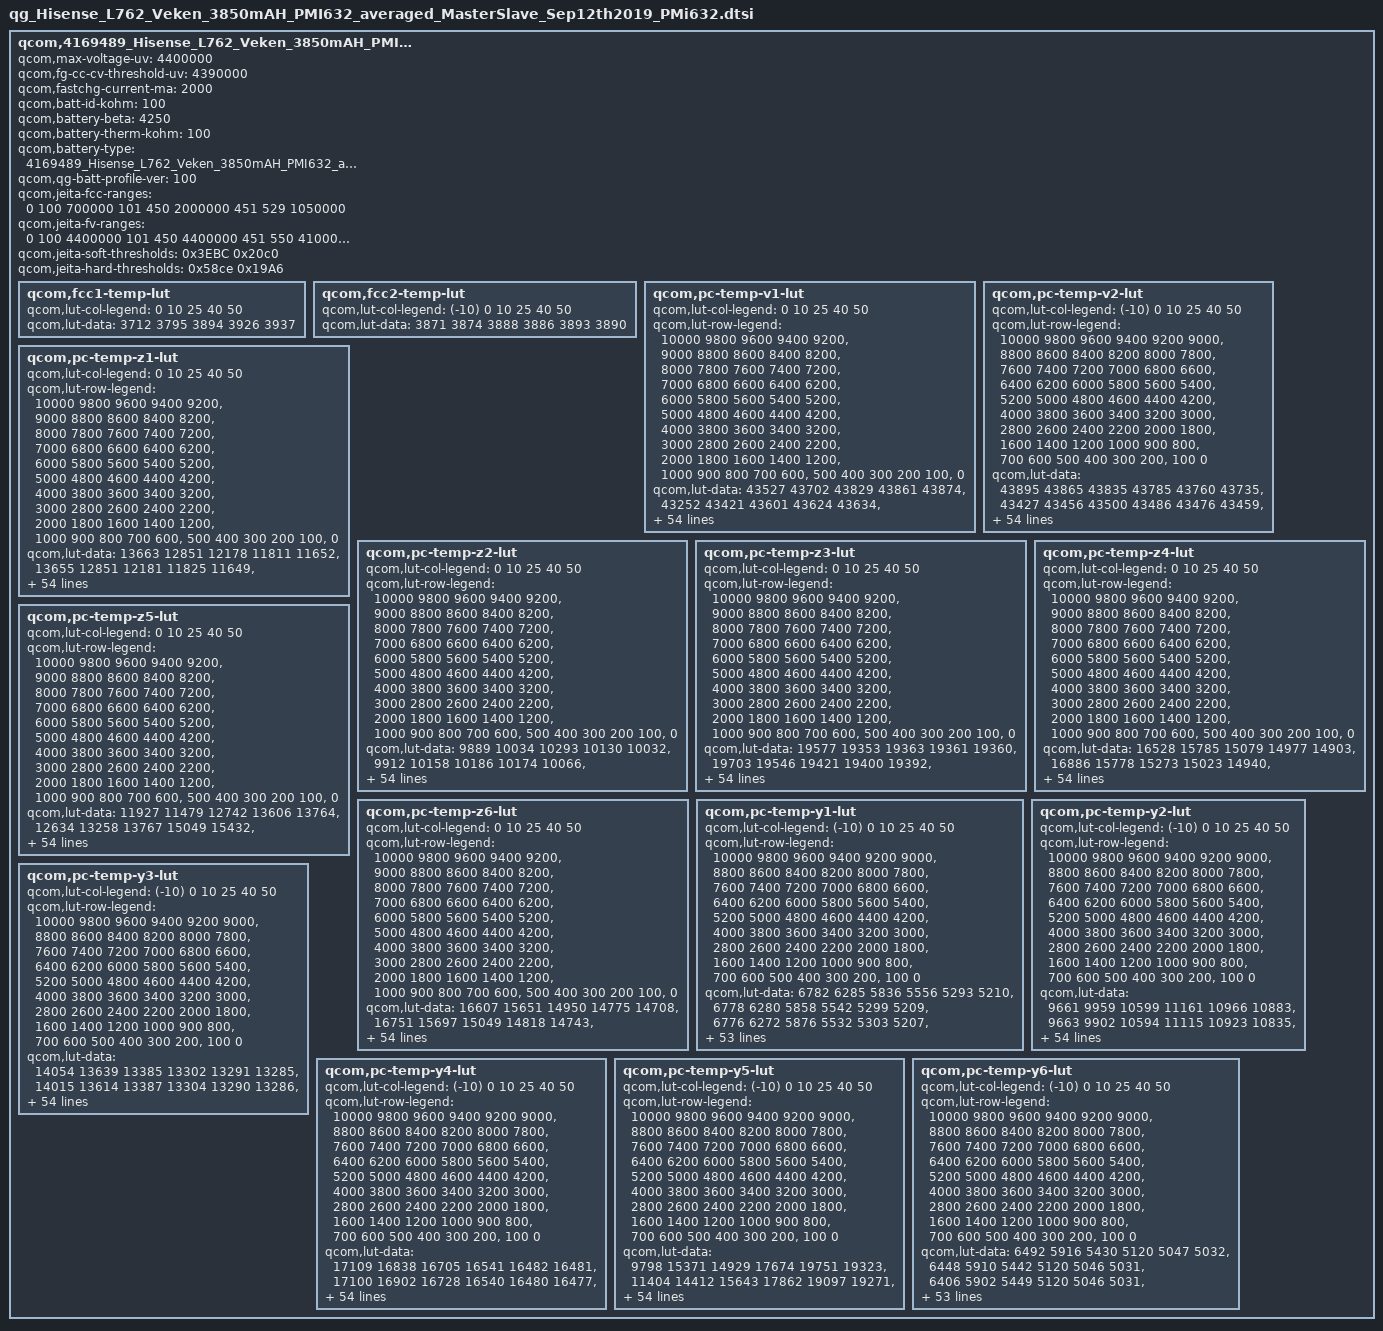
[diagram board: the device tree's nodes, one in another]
qcom,4169489_Hisense_L762_Veken_3850mAH_PMI632 {
    /* 4169489_Hisense_L762_Veken_3850mAH_PMI632_averaged_MasterSlave_Sep12th2019 */
    qcom,max-voltage-uv = <4400000>;
    qcom,fg-cc-cv-threshold-uv = <4390000>;
    qcom,fastchg-current-ma = <2000>;
    qcom,batt-id-kohm = <100>;
    qcom,battery-beta = <4250>;
    qcom,battery-therm-kohm = <100>;
    qcom,battery-type = "4169489_Hisense_L762_Veken_3850mAH_PMI632_averaged_MasterSlave_Sep12th2019";
    qcom,qg-batt-profile-ver = <100>;

	qcom,jeita-fcc-ranges = <0  100   700000
				 101 450  2000000
				 451 529  1050000>;
	qcom,jeita-fv-ranges =  <0  100  4400000
				 101 450  4400000
				 451 550  4100000>;
	/* COOL = 10 DegC, WARM = 45 DegC */
	qcom,jeita-soft-thresholds = <0x3EBC 0x20c0>;
	/* COLD = 0 DegC, HOT = 53 DegC */
	qcom,jeita-hard-thresholds = <0x58ce 0x19A6>;
	qcom,fcc1-temp-lut {
		qcom,lut-col-legend = <0 10 25 40 50>;
		qcom,lut-data = <3712 3795 3894 3926 3937>;
	};

	qcom,fcc2-temp-lut {
		qcom,lut-col-legend = <(-10) 0 10 25 40 50>;
		qcom,lut-data = <3871 3874 3888 3886 3893 3890>;
	};

	qcom,pc-temp-v1-lut {
		qcom,lut-col-legend = <0 10 25 40 50>;
		qcom,lut-row-legend = <10000 9800 9600 9400 9200>,
			<9000 8800 8600 8400 8200>,
			<8000 7800 7600 7400 7200>,
			<7000 6800 6600 6400 6200>,
			<6000 5800 5600 5400 5200>,
			<5000 4800 4600 4400 4200>,
			<4000 3800 3600 3400 3200>,
			<3000 2800 2600 2400 2200>,
			<2000 1800 1600 1400 1200>,
			<1000 900 800 700 600>,
			<500 400 300 200 100>,
			<0>;
		qcom,lut-data = <43527 43702 43829 43861 43874>,
			<43252 43421 43601 43624 43634>,
			<42995 43159 43348 43383 43402>,
			<42752 42914 43095 43144 43165>,
			<42519 42682 42852 42907 42928>,
			<42296 42455 42613 42670 42691>,
			<42082 42236 42379 42435 42455>,
			<41874 42021 42150 42202 42222>,
			<41676 41805 41924 41971 41992>,
			<41484 41594 41699 41744 41765>,
			<41304 41398 41478 41518 41538>,
			<41117 41217 41275 41299 41318>,
			<40908 41027 41092 41085 41101>,
			<40684 40806 40895 40876 40891>,
			<40453 40572 40649 40664 40685>,
			<40188 40341 40394 40454 40485>,
			<39948 40096 40195 40263 40294>,
			<39798 39898 40025 40094 40114>,
			<39691 39778 39868 39932 39941>,
			<39588 39682 39735 39775 39779>,
			<39482 39567 39599 39619 39625>,
			<39378 39431 39403 39430 39442>,
			<39269 39277 39139 39178 39193>,
			<39159 39079 38928 38954 38965>,
			<39047 38857 38783 38809 38818>,
			<38927 38698 38666 38692 38703>,
			<38802 38584 38573 38588 38594>,
			<38690 38496 38497 38493 38490>,
			<38583 38432 38425 38405 38395>,
			<38490 38381 38355 38320 38310>,
			<38425 38340 38291 38243 38234>,
			<38372 38308 38234 38177 38164>,
			<38328 38277 38182 38121 38101>,
			<38291 38247 38135 38067 38041>,
			<38259 38219 38093 38017 37985>,
			<38227 38188 38054 37968 37930>,
			<38196 38158 38017 37921 37874>,
			<38161 38122 37981 37876 37819>,
			<38122 38066 37929 37816 37750>,
			<38073 37980 37846 37728 37659>,
			<38002 37879 37745 37624 37553>,
			<37877 37759 37635 37516 37442>,
			<37733 37620 37507 37393 37317>,
			<37571 37451 37347 37236 37158>,
			<37406 37310 37194 37092 37019>,
			<37287 37204 37090 37000 36940>,
			<37241 37181 37060 36969 36911>,
			<37205 37150 37038 36950 36891>,
			<37175 37120 37024 36932 36872>,
			<37133 37083 36989 36891 36825>,
			<37000 36939 36815 36681 36592>,
			<36604 36535 36405 36262 36171>,
			<36049 35979 35847 35705 35613>,
			<35302 35225 35088 34943 34856>,
			<34127 34055 33913 33769 33673>,
			<30000 30000 30000 30000 30000>;
	};

	qcom,pc-temp-v2-lut {
		qcom,lut-col-legend = <(-10) 0 10 25 40 50>;
		qcom,lut-row-legend = <10000 9800 9600 9400 9200 9000>,
			<8800 8600 8400 8200 8000 7800>,
			<7600 7400 7200 7000 6800 6600>,
			<6400 6200 6000 5800 5600 5400>,
			<5200 5000 4800 4600 4400 4200>,
			<4000 3800 3600 3400 3200 3000>,
			<2800 2600 2400 2200 2000 1800>,
			<1600 1400 1200 1000 900 800>,
			<700 600 500 400 300 200>,
			<100 0>;
		qcom,lut-data = <43895 43865 43835 43785 43760 43735>,
			<43427 43456 43500 43486 43476 43459>,
			<43015 43091 43192 43205 43206 43194>,
			<42672 42778 42917 42943 42949 42941>,
			<42383 42504 42670 42699 42706 42700>,
			<42115 42264 42430 42461 42467 42463>,
			<41834 42062 42185 42224 42232 42229>,
			<41583 41875 41947 41992 42000 41997>,
			<41424 41635 41729 41765 41771 41769>,
			<41314 41329 41526 41544 41545 41543>,
			<41211 41153 41327 41327 41324 41321>,
			<41103 41117 41130 41114 41108 41103>,
			<40967 41089 40933 40904 40896 40889>,
			<40671 40916 40731 40699 40691 40685>,
			<40055 40355 40522 40493 40490 40486>,
			<39596 39896 40299 40287 40296 40294>,
			<39403 39668 40033 40066 40109 40107>,
			<39257 39484 39768 39860 39929 39928>,
			<39080 39297 39561 39708 39762 39761>,
			<38889 39115 39385 39587 39606 39604>,
			<38721 38933 39203 39435 39426 39426>,
			<38579 38736 38998 39193 39195 39202>,
			<38459 38553 38802 38941 38964 38976>,
			<38367 38416 38639 38758 38785 38793>,
			<38292 38302 38495 38606 38629 38630>,
			<38225 38218 38362 38476 38497 38493>,
			<38165 38157 38226 38365 38385 38380>,
			<38109 38107 38114 38266 38286 38281>,
			<38053 38059 38043 38174 38195 38191>,
			<37999 38017 37989 38090 38112 38110>,
			<37944 37975 37943 38014 38040 38037>,
			<37887 37933 37904 37943 37977 37971>,
			<37829 37891 37867 37881 37916 37907>,
			<37768 37848 37830 37827 37849 37840>,
			<37705 37805 37794 37781 37777 37770>,
			<37640 37758 37754 37733 37701 37686>,
			<37572 37706 37711 37684 37618 37581>,
			<37504 37647 37661 37630 37534 37477>,
			<37438 37580 37599 37563 37456 37393>,
			<37373 37505 37524 37485 37378 37315>,
			<37309 37415 37434 37398 37296 37234>,
			<37250 37300 37321 37298 37208 37151>,
			<37190 37185 37198 37182 37094 37040>,
			<37125 37081 37068 37047 36955 36896>,
			<37047 36995 36955 36922 36857 36805>,
			<36934 36921 36877 36865 36808 36758>,
			<36870 36887 36844 36851 36796 36748>,
			<36778 36838 36810 36835 36781 36733>,
			<36642 36755 36748 36804 36755 36703>,
			<36414 36589 36633 36726 36670 36614>,
			<36040 36256 36336 36441 36355 36278>,
			<35523 35741 35823 35975 35857 35780>,
			<34827 35046 35137 35346 35203 35126>,
			<33943 34142 34149 34477 34326 34250>,
			<32741 32959 32725 33232 33085 33031>,
			<30204 29375 28981 28535 28714 29147>;
	};

	qcom,pc-temp-z1-lut {
		qcom,lut-col-legend = <0 10 25 40 50>;
		qcom,lut-row-legend = <10000 9800 9600 9400 9200>,
			<9000 8800 8600 8400 8200>,
			<8000 7800 7600 7400 7200>,
			<7000 6800 6600 6400 6200>,
			<6000 5800 5600 5400 5200>,
			<5000 4800 4600 4400 4200>,
			<4000 3800 3600 3400 3200>,
			<3000 2800 2600 2400 2200>,
			<2000 1800 1600 1400 1200>,
			<1000 900 800 700 600>,
			<500 400 300 200 100>,
			<0>;
		qcom,lut-data = <13663 12851 12178 11811 11652>,
			<13655 12851 12181 11825 11649>,
			<13646 12851 12183 11819 11646>,
			<13636 12849 12185 11811 11638>,
			<13625 12844 12180 11802 11630>,
			<13604 12833 12173 11788 11623>,
			<13589 12807 12164 11777 11617>,
			<13587 12790 12151 11769 11611>,
			<13587 12785 12141 11764 11606>,
			<13579 12782 12136 11760 11603>,
			<13553 12775 12132 11758 11601>,
			<13524 12760 12134 11757 11600>,
			<13501 12743 12144 11759 11599>,
			<13477 12718 12150 11761 11598>,
			<13447 12692 12129 11758 11597>,
			<13399 12689 12099 11748 11596>,
			<13362 12696 12096 11744 11596>,
			<13360 12702 12106 11747 11596>,
			<13367 12702 12112 11751 11597>,
			<13375 12702 12116 11752 11597>,
			<13386 12707 12120 11754 11598>,
			<13398 12729 12125 11756 11598>,
			<13406 12748 12132 11757 11599>,
			<13417 12755 12136 11759 11599>,
			<13425 12759 12136 11761 11600>,
			<13429 12759 12136 11764 11602>,
			<13436 12756 12141 11768 11605>,
			<13442 12755 12149 11773 11609>,
			<13451 12757 12155 11777 11613>,
			<13459 12761 12159 11781 11616>,
			<13458 12766 12163 11785 11619>,
			<13451 12774 12164 11789 11622>,
			<13450 12783 12165 11793 11626>,
			<13471 12792 12167 11797 11630>,
			<13498 12803 12173 11802 11635>,
			<13507 12813 12180 11808 11639>,
			<13508 12824 12185 11813 11643>,
			<13512 12836 12190 11819 11648>,
			<13547 12855 12195 11824 11652>,
			<13597 12882 12202 11827 11656>,
			<13609 12901 12210 11830 11660>,
			<13596 12907 12220 11834 11665>,
			<13597 12913 12229 11840 11670>,
			<13651 12925 12230 11849 11675>,
			<13659 12951 12239 11855 11678>,
			<13631 12925 12239 11857 11680>,
			<13647 12966 12237 11855 11680>,
			<13676 12914 12234 11857 11682>,
			<13674 12937 12259 11859 11685>,
			<13648 12950 12243 11865 11690>,
			<13664 12984 12250 11877 11700>,
			<13731 12964 12276 11888 11711>,
			<13723 12980 12288 11902 11722>,
			<13752 13032 12315 11922 11744>,
			<13752 13032 12315 11922 11744>,
			<13752 13032 12315 11922 11744>;
	};

	qcom,pc-temp-z2-lut {
		qcom,lut-col-legend = <0 10 25 40 50>;
		qcom,lut-row-legend = <10000 9800 9600 9400 9200>,
			<9000 8800 8600 8400 8200>,
			<8000 7800 7600 7400 7200>,
			<7000 6800 6600 6400 6200>,
			<6000 5800 5600 5400 5200>,
			<5000 4800 4600 4400 4200>,
			<4000 3800 3600 3400 3200>,
			<3000 2800 2600 2400 2200>,
			<2000 1800 1600 1400 1200>,
			<1000 900 800 700 600>,
			<500 400 300 200 100>,
			<0>;
		qcom,lut-data = <9889 10034 10293 10130 10032>,
			<9912 10158 10186 10174 10066>,
			<9964 10200 10254 10205 10095>,
			<10004 10176 10306 10236 10118>,
			<10014 10144 10276 10224 10119>,
			<10014 10161 10218 10165 10093>,
			<10016 10267 10222 10117 10066>,
			<10025 10325 10414 10090 10043>,
			<10036 10218 10554 10073 10020>,
			<10039 10069 10415 10073 10002>,
			<10037 10036 10187 10083 9981>,
			<10032 10028 10144 10092 9969>,
			<10013 10025 10154 10093 9957>,
			<9978 10034 10172 10092 9946>,
			<9957 10051 10400 10100 9951>,
			<9946 10061 10714 10115 9960>,
			<9939 10067 10688 10108 9970>,
			<9935 10075 10362 10063 9983>,
			<9933 10088 10182 10027 9999>,
			<9932 10108 10202 10034 10014>,
			<9935 10133 10239 10060 10031>,
			<9943 10173 10283 10106 10066>,
			<9952 10204 10344 10221 10186>,
			<9960 10211 10367 10298 10278>,
			<9969 10209 10324 10240 10228>,
			<9983 10207 10275 10143 10124>,
			<10003 10210 10277 10137 10122>,
			<10022 10215 10300 10213 10271>,
			<10042 10225 10313 10269 10372>,
			<10061 10243 10313 10268 10289>,
			<10075 10255 10312 10249 10139>,
			<10088 10261 10314 10219 10050>,
			<10100 10266 10319 10174 9984>,
			<10112 10274 10321 10152 9959>,
			<10125 10283 10325 10155 9969>,
			<10140 10292 10330 10164 9990>,
			<10161 10299 10342 10170 10018>,
			<10172 10308 10364 10179 10062>,
			<10097 10322 10388 10196 10100>,
			<9966 10347 10418 10254 10134>,
			<9940 10366 10439 10305 10156>,
			<10047 10375 10441 10302 10152>,
			<10137 10385 10441 10290 10142>,
			<10228 10397 10445 10290 10163>,
			<10153 10901 10470 10300 10172>,
			<10471 12468 10514 10256 10132>,
			<10253 12680 10487 10237 10133>,
			<10220 20619 10477 10271 10140>,
			<10461 22290 10473 10283 10167>,
			<10450 17840 10510 10364 10260>,
			<10311 18937 10560 10286 10155>,
			<9942 14584 10511 10148 9992>,
			<9865 15669 10440 10106 9945>,
			<9773 14341 10368 10054 9906>,
			<9773 14341 10368 10054 9906>,
			<9773 14341 10368 10054 9906>;
	};

	qcom,pc-temp-z3-lut {
		qcom,lut-col-legend = <0 10 25 40 50>;
		qcom,lut-row-legend = <10000 9800 9600 9400 9200>,
			<9000 8800 8600 8400 8200>,
			<8000 7800 7600 7400 7200>,
			<7000 6800 6600 6400 6200>,
			<6000 5800 5600 5400 5200>,
			<5000 4800 4600 4400 4200>,
			<4000 3800 3600 3400 3200>,
			<3000 2800 2600 2400 2200>,
			<2000 1800 1600 1400 1200>,
			<1000 900 800 700 600>,
			<500 400 300 200 100>,
			<0>;
		qcom,lut-data = <19577 19353 19363 19361 19360>,
			<19703 19546 19421 19400 19392>,
			<19756 19639 19472 19427 19404>,
			<19786 19663 19501 19443 19419>,
			<19793 19675 19505 19449 19431>,
			<19794 19679 19507 19453 19439>,
			<19793 19681 19510 19454 19443>,
			<19783 19681 19521 19453 19442>,
			<19768 19672 19528 19450 19438>,
			<19765 19660 19517 19446 19434>,
			<19766 19650 19498 19437 19428>,
			<19768 19641 19488 19431 19423>,
			<19771 19632 19478 19428 19418>,
			<19776 19618 19474 19425 19412>,
			<19777 19603 19484 19425 19408>,
			<19785 19597 19498 19424 19405>,
			<19794 19595 19495 19422 19402>,
			<19784 19592 19473 19412 19398>,
			<19749 19571 19455 19402 19393>,
			<19717 19542 19448 19393 19386>,
			<19694 19536 19443 19386 19378>,
			<19676 19542 19445 19386 19377>,
			<19674 19548 19453 19396 19383>,
			<19680 19553 19457 19403 19389>,
			<19687 19559 19447 19394 19382>,
			<19693 19560 19437 19377 19368>,
			<19700 19558 19435 19375 19369>,
			<19703 19556 19435 19391 19407>,
			<19704 19556 19437 19404 19434>,
			<19704 19554 19445 19417 19433>,
			<19700 19553 19453 19431 19428>,
			<19692 19552 19456 19431 19423>,
			<19683 19550 19460 19424 19414>,
			<19675 19548 19460 19417 19405>,
			<19665 19546 19457 19410 19396>,
			<19655 19543 19452 19403 19387>,
			<19645 19538 19447 19396 19380>,
			<19628 19533 19441 19388 19374>,
			<19509 19529 19437 19386 19372>,
			<19319 19526 19435 19386 19371>,
			<19264 19522 19433 19387 19371>,
			<19263 19517 19428 19385 19373>,
			<19262 19511 19422 19383 19377>,
			<19261 19506 19420 19384 19383>,
			<19261 19415 19412 19382 19383>,
			<19260 19355 19399 19368 19365>,
			<19261 19258 19396 19367 19360>,
			<19261 19256 19394 19358 19350>,
			<19260 19256 19367 19352 19345>,
			<19260 19257 19369 19346 19335>,
			<19260 19256 19365 19364 19360>,
			<19262 19258 19365 19384 19379>,
			<19263 19257 19370 19379 19381>,
			<19264 19257 19369 19381 19376>,
			<19264 19257 19369 19381 19376>,
			<19264 19257 19369 19381 19376>;
	};

	qcom,pc-temp-z4-lut {
		qcom,lut-col-legend = <0 10 25 40 50>;
		qcom,lut-row-legend = <10000 9800 9600 9400 9200>,
			<9000 8800 8600 8400 8200>,
			<8000 7800 7600 7400 7200>,
			<7000 6800 6600 6400 6200>,
			<6000 5800 5600 5400 5200>,
			<5000 4800 4600 4400 4200>,
			<4000 3800 3600 3400 3200>,
			<3000 2800 2600 2400 2200>,
			<2000 1800 1600 1400 1200>,
			<1000 900 800 700 600>,
			<500 400 300 200 100>,
			<0>;
		qcom,lut-data = <16528 15785 15079 14977 14903>,
			<16886 15778 15273 15023 14940>,
			<16668 15741 15194 14994 14932>,
			<16346 15574 15100 14934 14895>,
			<16102 15345 15029 14890 14862>,
			<15880 15196 14961 14855 14832>,
			<15698 15074 14898 14824 14805>,
			<15558 14991 14831 14794 14779>,
			<15441 14942 14789 14771 14757>,
			<15340 14904 14776 14757 14747>,
			<15252 14869 14769 14748 14742>,
			<15175 14835 14760 14740 14738>,
			<15106 14810 14750 14733 14733>,
			<15045 14794 14742 14726 14727>,
			<15007 14783 14730 14721 14721>,
			<14987 14781 14715 14717 14715>,
			<14968 14786 14714 14712 14710>,
			<14940 14789 14716 14702 14704>,
			<14904 14775 14714 14696 14699>,
			<14875 14748 14703 14696 14697>,
			<14857 14735 14693 14696 14695>,
			<14842 14726 14715 14706 14699>,
			<14823 14721 14801 14774 14765>,
			<14796 14759 14856 14835 14830>,
			<14776 14841 14878 14854 14844>,
			<14773 14879 14893 14866 14852>,
			<14778 14892 14886 14863 14844>,
			<14786 14895 14863 14829 14788>,
			<14800 14885 14838 14795 14741>,
			<14811 14865 14813 14767 14727>,
			<14811 14846 14790 14742 14719>,
			<14806 14825 14772 14728 14712>,
			<14799 14804 14756 14720 14706>,
			<14790 14786 14748 14716 14704>,
			<14778 14769 14742 14714 14704>,
			<14766 14755 14738 14714 14704>,
			<14752 14740 14735 14714 14704>,
			<14744 14729 14731 14714 14705>,
			<14847 14728 14730 14714 14707>,
			<15032 14730 14734 14723 14720>,
			<15085 14730 14738 14732 14732>,
			<15080 14727 14731 14727 14726>,
			<15071 14723 14719 14717 14713>,
			<15057 14718 14714 14715 14714>,
			<14980 14764 14698 14704 14706>,
			<14958 14797 14680 14685 14684>,
			<14953 14888 14671 14679 14680>,
			<14943 14876 14656 14668 14671>,
			<14933 14866 14667 14649 14649>,
			<14927 14860 14655 14641 14639>,
			<14927 14866 14676 14656 14660>,
			<14961 14894 14699 14660 14668>,
			<14985 14907 14699 14670 14673>,
			<15003 14918 14704 14672 14681>,
			<15003 14918 14704 14672 14681>,
			<15003 14918 14704 14672 14681>;
	};

	qcom,pc-temp-z5-lut {
		qcom,lut-col-legend = <0 10 25 40 50>;
		qcom,lut-row-legend = <10000 9800 9600 9400 9200>,
			<9000 8800 8600 8400 8200>,
			<8000 7800 7600 7400 7200>,
			<7000 6800 6600 6400 6200>,
			<6000 5800 5600 5400 5200>,
			<5000 4800 4600 4400 4200>,
			<4000 3800 3600 3400 3200>,
			<3000 2800 2600 2400 2200>,
			<2000 1800 1600 1400 1200>,
			<1000 900 800 700 600>,
			<500 400 300 200 100>,
			<0>;
		qcom,lut-data = <11927 11479 12742 13606 13764>,
			<12634 13258 13767 15049 15432>,
			<13186 14461 15042 16254 16030>,
			<13661 15157 16068 17160 17220>,
			<14073 15697 16590 17774 18343>,
			<14441 16226 16987 18212 19393>,
			<14755 16712 17785 18696 20359>,
			<14991 17286 19809 19436 21261>,
			<15204 18139 21298 20113 22057>,
			<15517 19185 21591 20413 22478>,
			<16098 20267 21691 20640 22617>,
			<16666 21494 21741 20987 22596>,
			<17205 22413 22109 21624 22675>,
			<17850 23166 22748 22504 22946>,
			<18226 23816 27077 24154 23524>,
			<19692 24026 32655 26524 24616>,
			<21265 24687 32244 27070 25648>,
			<21018 25062 27032 25270 26740>,
			<19419 24027 24267 23738 27489>,
			<18367 22449 27218 23851 27274>,
			<18151 22981 32035 24295 26513>,
			<18016 30466 35926 25056 25986>,
			<18337 38046 40120 26808 26075>,
			<20720 42806 41520 27900 25957>,
			<24186 48032 34997 24543 22781>,
			<29407 48815 26689 18643 17418>,
			<36232 44796 23832 16975 16589>,
			<40062 40286 22114 17472 20066>,
			<43718 37831 21670 18663 23265>,
			<46174 35893 22860 21353 24428>,
			<45455 34800 24632 24536 25281>,
			<43928 34037 26572 25915 26034>,
			<42253 33675 29588 26761 26776>,
			<40430 34247 32413 27548 27120>,
			<38403 35652 35382 28824 27162>,
			<36369 36767 37418 29890 27168>,
			<34128 37541 37671 29646 27127>,
			<31089 38088 37362 28539 26987>,
			<23512 38683 36755 27766 26723>,
			<13775 39976 35478 27427 25514>,
			<11142 40188 33738 27085 24247>,
			<11198 37167 31076 25721 24029>,
			<11237 34605 28543 23921 24287>,
			<11256 33930 27862 24580 26340>,
			<11510 26918 28359 24993 27554>,
			<11505 22167 27339 22044 22238>,
			<11480 11560 26454 21827 20392>,
			<11445 11429 27589 20752 19106>,
			<11405 11414 19566 22319 21477>,
			<11409 11438 21164 22250 22139>,
			<11443 11468 18412 24863 26719>,
			<11520 11426 16264 24137 23631>,
			<11370 11306 16107 20220 21345>,
			<11279 11226 15541 19135 17589>,
			<11279 11226 15541 19135 17589>,
			<11279 11226 15541 19135 17589>;
	};

	qcom,pc-temp-z6-lut {
		qcom,lut-col-legend = <0 10 25 40 50>;
		qcom,lut-row-legend = <10000 9800 9600 9400 9200>,
			<9000 8800 8600 8400 8200>,
			<8000 7800 7600 7400 7200>,
			<7000 6800 6600 6400 6200>,
			<6000 5800 5600 5400 5200>,
			<5000 4800 4600 4400 4200>,
			<4000 3800 3600 3400 3200>,
			<3000 2800 2600 2400 2200>,
			<2000 1800 1600 1400 1200>,
			<1000 900 800 700 600>,
			<500 400 300 200 100>,
			<0>;
		qcom,lut-data = <16607 15651 14950 14775 14708>,
			<16751 15697 15049 14818 14743>,
			<16627 15707 15032 14813 14743>,
			<16442 15622 15007 14796 14736>,
			<16298 15494 14977 14782 14729>,
			<16164 15410 14939 14766 14720>,
			<16048 15341 14909 14750 14709>,
			<15951 15285 14884 14737 14697>,
			<15868 15242 14864 14724 14685>,
			<15800 15207 14847 14714 14677>,
			<15744 15175 14832 14705 14672>,
			<15693 15148 14821 14698 14666>,
			<15636 15122 14812 14693 14661>,
			<15580 15094 14806 14689 14655>,
			<15542 15069 14803 14686 14650>,
			<15519 15061 14800 14682 14645>,
			<15498 15059 14795 14677 14640>,
			<15469 15057 14784 14668 14636>,
			<15433 15042 14776 14660 14631>,
			<15406 15020 14770 14655 14626>,
			<15391 15015 14765 14652 14621>,
			<15380 15018 14776 14656 14622>,
			<15376 15024 14819 14692 14655>,
			<15374 15047 14845 14722 14685>,
			<15374 15086 14852 14724 14686>,
			<15379 15104 14854 14723 14684>,
			<15391 15110 14850 14720 14681>,
			<15400 15113 14841 14714 14678>,
			<15410 15110 14835 14709 14674>,
			<15418 15103 14830 14706 14669>,
			<15418 15097 14826 14702 14663>,
			<15416 15090 14822 14698 14657>,
			<15413 15083 14818 14691 14651>,
			<15409 15077 14815 14686 14646>,
			<15404 15072 14812 14683 14641>,
			<15399 15068 14810 14680 14637>,
			<15393 15064 14808 14676 14634>,
			<15389 15062 14805 14672 14631>,
			<15386 15064 14804 14671 14631>,
			<15383 15070 14808 14676 14636>,
			<15384 15076 14812 14681 14641>,
			<15394 15080 14809 14679 14640>,
			<15406 15084 14805 14675 14638>,
			<15417 15091 14805 14676 14641>,
			<15409 15081 14800 14672 14639>,
			<15404 15074 14790 14657 14621>,
			<15405 15066 14784 14653 14616>,
			<15401 15061 14778 14645 14608>,
			<15400 15060 14770 14634 14595>,
			<15402 15063 14768 14628 14587>,
			<15416 15075 14781 14646 14610>,
			<15443 15096 14796 14662 14627>,
			<15467 15112 14804 14668 14635>,
			<15498 15138 14815 14675 14640>,
			<15498 15138 14815 14675 14640>,
			<15498 15138 14815 14675 14640>;
	};

	qcom,pc-temp-y1-lut {
		qcom,lut-col-legend = <(-10) 0 10 25 40 50>;
		qcom,lut-row-legend = <10000 9800 9600 9400 9200 9000>,
			<8800 8600 8400 8200 8000 7800>,
			<7600 7400 7200 7000 6800 6600>,
			<6400 6200 6000 5800 5600 5400>,
			<5200 5000 4800 4600 4400 4200>,
			<4000 3800 3600 3400 3200 3000>,
			<2800 2600 2400 2200 2000 1800>,
			<1600 1400 1200 1000 900 800>,
			<700 600 500 400 300 200>,
			<100 0>;
		qcom,lut-data = <6782 6285 5836 5556 5293 5210>,
			<6778 6280 5858 5542 5299 5209>,
			<6776 6272 5876 5532 5303 5207>,
			<6774 6266 5888 5524 5305 5205>,
			<6774 6261 5895 5520 5306 5204>,
			<6773 6260 5898 5518 5306 5203>,
			<6775 6262 5892 5522 5304 5202>,
			<6781 6265 5884 5527 5301 5202>,
			<6793 6266 5882 5526 5300 5201>,
			<6819 6265 5883 5519 5298 5200>,
			<6834 6267 5884 5515 5297 5199>,
			<6827 6275 5884 5515 5295 5198>,
			<6818 6284 5885 5515 5293 5197>,
			<6817 6286 5885 5515 5291 5197>,
			<6823 6280 5887 5516 5289 5197>,
			<6826 6278 5889 5517 5289 5197>,
			<6819 6280 5894 5521 5294 5197>,
			<6810 6283 5900 5527 5299 5197>,
			<6811 6287 5905 5527 5299 5197>,
			<6819 6292 5909 5526 5296 5197>,
			<6822 6293 5910 5525 5295 5197>,
			<6815 6290 5907 5526 5295 5197>,
			<6808 6287 5904 5527 5296 5198>,
			<6810 6288 5904 5529 5297 5199>,
			<6823 6294 5906 5534 5301 5201>,
			<6835 6296 5907 5536 5304 5203>,
			<6843 6286 5905 5536 5306 5205>,
			<6849 6276 5904 5535 5307 5207>,
			<6846 6275 5903 5537 5310 5208>,
			<6835 6279 5901 5542 5314 5210>,
			<6831 6281 5899 5545 5317 5212>,
			<6838 6287 5898 5547 5320 5215>,
			<6846 6295 5899 5548 5324 5218>,
			<6838 6289 5903 5550 5327 5220>,
			<6813 6274 5912 5553 5330 5222>,
			<6804 6268 5913 5554 5332 5224>,
			<6823 6276 5908 5555 5336 5226>,
			<6844 6284 5902 5555 5338 5228>,
			<6834 6285 5900 5560 5338 5230>,
			<6799 6280 5900 5570 5338 5232>,
			<6783 6278 5902 5576 5339 5234>,
			<6782 6286 5910 5581 5342 5235>,
			<6782 6286 5909 5583 5346 5238>,
			<6787 6269 5900 5584 5351 5242>,
			<6842 6286 5902 5587 5359 5245>,
			<6867 6332 5921 5595 5364 5250>,
			<6893 6323 5932 5596 5361 5249>,
			<6918 6334 5922 5608 5361 5248>,
			<6913 6324 5930 5596 5360 5250>,
			<7014 6339 5952 5598 5365 5251>,
			<7062 6343 5957 5595 5365 5253>,
			<6930 6366 5950 5608 5375 5259>,
			<7017 6376 5981 5612 5380 5267>,
			<7133 6416 6003 5630 5396 5278>,
			<7133 6416 6003 5630 5396 5278>,
			<7133 6416 6003 5630 5396 5278>;
	};

	qcom,pc-temp-y2-lut {
		qcom,lut-col-legend = <(-10) 0 10 25 40 50>;
		qcom,lut-row-legend = <10000 9800 9600 9400 9200 9000>,
			<8800 8600 8400 8200 8000 7800>,
			<7600 7400 7200 7000 6800 6600>,
			<6400 6200 6000 5800 5600 5400>,
			<5200 5000 4800 4600 4400 4200>,
			<4000 3800 3600 3400 3200 3000>,
			<2800 2600 2400 2200 2000 1800>,
			<1600 1400 1200 1000 900 800>,
			<700 600 500 400 300 200>,
			<100 0>;
		qcom,lut-data = <9661 9959 10599 11161 10966 10883>,
			<9663 9902 10594 11115 10923 10835>,
			<9665 9899 10594 11071 10875 10789>,
			<9668 9930 10598 11030 10828 10746>,
			<9670 9980 10604 10991 10788 10709>,
			<9671 10029 10611 10956 10760 10679>,
			<9672 10110 10626 10922 10740 10654>,
			<9673 10200 10641 10891 10725 10635>,
			<9672 10202 10618 10871 10714 10626>,
			<9670 10094 10517 10856 10699 10620>,
			<9668 10031 10467 10838 10695 10617>,
			<9669 10106 10718 10804 10717 10614>,
			<9670 10231 11034 10774 10742 10609>,
			<9670 10294 11025 10794 10740 10600>,
			<9668 10248 10863 10889 10722 10585>,
			<9667 10204 10788 10968 10715 10579>,
			<9667 9993 10877 11008 10767 10606>,
			<9667 9732 10993 11046 10852 10656>,
			<9667 9697 11037 11122 10932 10726>,
			<9666 9691 11063 11239 11020 10836>,
			<9666 9686 11073 11285 11048 10896>,
			<9666 9682 11071 11238 11013 10923>,
			<9666 9679 11063 11178 10978 10937>,
			<9665 9679 11051 11156 10976 10918>,
			<9665 9679 11026 11141 10975 10875>,
			<9665 9679 10966 11138 10980 10860>,
			<9664 9677 10626 11191 11013 10879>,
			<9664 9674 10282 11247 11049 10908>,
			<9664 9673 10253 11255 11058 10937>,
			<9664 9671 10351 11256 11056 10969>,
			<9664 9669 10394 11256 11061 10987>,
			<9664 9668 10416 11258 11097 10995>,
			<9663 9667 10429 11257 11129 11004>,
			<9663 9666 10277 11251 11137 11027>,
			<9663 9664 9946 11241 11143 11058>,
			<9663 9664 9793 11227 11133 11057>,
			<9662 9663 9741 11201 11097 10983>,
			<9662 9662 9711 11168 11065 10912>,
			<9662 9662 9694 11120 11052 10900>,
			<9661 9661 9683 11054 11041 10907>,
			<9661 9661 9676 10986 11027 10913>,
			<9661 9660 9672 10917 11003 10919>,
			<9661 9660 9669 10849 10970 10891>,
			<9661 9660 9666 10782 10922 10818>,
			<9660 9659 9664 10701 10844 10696>,
			<9660 9659 9664 10694 10789 10640>,
			<9660 9659 9663 10687 10805 10647>,
			<9659 9659 9662 10690 10797 10713>,
			<9659 9658 9661 10697 10849 10686>,
			<9658 9658 9661 10689 10865 10702>,
			<9658 9658 9660 10653 10852 10654>,
			<9658 9657 9659 10602 10791 10581>,
			<9655 9657 9658 10561 10687 10513>,
			<9656 9655 9657 10512 10613 10460>,
			<9656 9655 9657 10512 10613 10460>,
			<9656 9655 9657 10512 10613 10460>;
	};

	qcom,pc-temp-y3-lut {
		qcom,lut-col-legend = <(-10) 0 10 25 40 50>;
		qcom,lut-row-legend = <10000 9800 9600 9400 9200 9000>,
			<8800 8600 8400 8200 8000 7800>,
			<7600 7400 7200 7000 6800 6600>,
			<6400 6200 6000 5800 5600 5400>,
			<5200 5000 4800 4600 4400 4200>,
			<4000 3800 3600 3400 3200 3000>,
			<2800 2600 2400 2200 2000 1800>,
			<1600 1400 1200 1000 900 800>,
			<700 600 500 400 300 200>,
			<100 0>;
		qcom,lut-data = <14054 13639 13385 13302 13291 13285>,
			<14015 13614 13387 13304 13290 13286>,
			<13973 13594 13391 13305 13290 13286>,
			<13930 13581 13396 13306 13290 13287>,
			<13886 13573 13400 13308 13290 13287>,
			<13842 13573 13401 13309 13290 13288>,
			<13800 13586 13401 13310 13291 13288>,
			<13756 13605 13400 13312 13291 13289>,
			<13696 13585 13408 13313 13292 13289>,
			<13612 13476 13438 13316 13292 13290>,
			<13571 13409 13454 13318 13293 13291>,
			<13586 13407 13410 13319 13296 13292>,
			<13608 13410 13353 13320 13300 13293>,
			<13605 13417 13350 13321 13302 13295>,
			<13581 13430 13363 13324 13303 13297>,
			<13566 13436 13369 13324 13304 13299>,
			<13565 13436 13368 13317 13305 13300>,
			<13567 13435 13365 13309 13306 13300>,
			<13570 13434 13361 13309 13305 13300>,
			<13576 13432 13354 13313 13302 13300>,
			<13579 13429 13348 13314 13298 13299>,
			<13576 13419 13341 13309 13294 13295>,
			<13574 13405 13335 13303 13291 13289>,
			<13578 13391 13331 13301 13289 13287>,
			<13594 13376 13327 13299 13289 13285>,
			<13612 13371 13320 13299 13288 13284>,
			<13630 13383 13289 13298 13287 13283>,
			<13649 13404 13262 13298 13287 13283>,
			<13670 13423 13266 13298 13286 13283>,
			<13695 13445 13282 13297 13284 13284>,
			<13721 13469 13292 13296 13284 13284>,
			<13750 13495 13305 13296 13286 13283>,
			<13782 13525 13320 13296 13287 13282>,
			<13815 13559 13330 13296 13287 13283>,
			<13850 13598 13338 13297 13286 13284>,
			<13888 13639 13348 13297 13286 13285>,
			<13927 13680 13359 13298 13286 13284>,
			<13968 13722 13373 13300 13286 13284>,
			<14008 13765 13391 13301 13287 13284>,
			<14049 13810 13412 13302 13288 13286>,
			<14090 13848 13437 13304 13289 13288>,
			<14129 13880 13467 13306 13290 13289>,
			<14173 13913 13502 13308 13289 13288>,
			<14222 13951 13544 13311 13285 13285>,
			<14278 13998 13592 13311 13287 13287>,
			<14247 13986 13603 13311 13294 13293>,
			<14308 14032 13639 13318 13299 13296>,
			<14370 14076 13683 13325 13301 13299>,
			<14431 14119 13716 13331 13304 13298>,
			<14496 14156 13754 13336 13303 13297>,
			<14564 14192 13772 13332 13299 13293>,
			<14679 14262 13855 13338 13300 13294>,
			<15006 14366 13998 13344 13306 13300>,
			<16166 14574 14158 13357 13317 13313>,
			<16166 14574 14158 13357 13317 13313>,
			<16166 14574 14158 13357 13317 13313>;
	};

	qcom,pc-temp-y4-lut {
		qcom,lut-col-legend = <(-10) 0 10 25 40 50>;
		qcom,lut-row-legend = <10000 9800 9600 9400 9200 9000>,
			<8800 8600 8400 8200 8000 7800>,
			<7600 7400 7200 7000 6800 6600>,
			<6400 6200 6000 5800 5600 5400>,
			<5200 5000 4800 4600 4400 4200>,
			<4000 3800 3600 3400 3200 3000>,
			<2800 2600 2400 2200 2000 1800>,
			<1600 1400 1200 1000 900 800>,
			<700 600 500 400 300 200>,
			<100 0>;
		qcom,lut-data = <17109 16838 16705 16541 16482 16481>,
			<17100 16902 16728 16540 16480 16477>,
			<17102 16958 16762 16539 16479 16474>,
			<17113 17003 16797 16538 16478 16472>,
			<17126 17033 16823 16536 16477 16470>,
			<17137 17043 16834 16536 16476 16469>,
			<17147 17027 16831 16535 16477 16470>,
			<17163 17005 16827 16535 16478 16471>,
			<17237 17037 16815 16535 16481 16472>,
			<17484 17217 16783 16539 16485 16473>,
			<17636 17395 16769 16544 16487 16475>,
			<17636 17539 16910 16547 16487 16477>,
			<17604 17647 17088 16552 16487 16480>,
			<17466 17559 17100 16563 16490 16483>,
			<17061 17143 17053 16587 16501 16486>,
			<16837 16896 17006 16609 16512 16491>,
			<16829 16870 16910 16627 16521 16497>,
			<16824 16854 16811 16646 16533 16507>,
			<16801 16831 16788 16666 16558 16526>,
			<16748 16793 16781 16694 16596 16557>,
			<16718 16749 16766 16702 16609 16568>,
			<16712 16688 16713 16638 16572 16546>,
			<16708 16637 16652 16558 16525 16516>,
			<16708 16634 16614 16527 16499 16495>,
			<16708 16639 16585 16507 16478 16475>,
			<16708 16642 16577 16500 16473 16468>,
			<16707 16641 16600 16498 16474 16470>,
			<16706 16640 16622 16497 16477 16473>,
			<16708 16641 16613 16498 16483 16478>,
			<16713 16644 16583 16501 16494 16487>,
			<16718 16649 16571 16502 16504 16497>,
			<16723 16657 16559 16502 16516 16513>,
			<16727 16668 16552 16501 16522 16523>,
			<16732 16680 16566 16502 16521 16524>,
			<16738 16694 16595 16505 16516 16524>,
			<16743 16708 16621 16507 16509 16521>,
			<16748 16722 16648 16509 16491 16496>,
			<16756 16734 16670 16510 16480 16477>,
			<16767 16738 16686 16511 16480 16478>,
			<16787 16740 16699 16513 16481 16481>,
			<16811 16737 16701 16517 16484 16487>,
			<16846 16714 16697 16532 16495 16501>,
			<16884 16696 16689 16540 16493 16497>,
			<16923 16686 16675 16543 16477 16465>,
			<16930 16696 16667 16546 16475 16461>,
			<16835 16698 16664 16539 16480 16480>,
			<16850 16721 16686 16554 16503 16513>,
			<16865 16757 16720 16574 16537 16546>,
			<16879 16792 16772 16606 16571 16582>,
			<16880 16809 16813 16636 16586 16591>,
			<16874 16800 16801 16596 16511 16498>,
			<16902 16800 16777 16600 16497 16490>,
			<17076 16827 16790 16619 16509 16492>,
			<18644 17065 16835 16666 16559 16527>,
			<18644 17065 16835 16666 16559 16527>,
			<18644 17065 16835 16666 16559 16527>;
	};

	qcom,pc-temp-y5-lut {
		qcom,lut-col-legend = <(-10) 0 10 25 40 50>;
		qcom,lut-row-legend = <10000 9800 9600 9400 9200 9000>,
			<8800 8600 8400 8200 8000 7800>,
			<7600 7400 7200 7000 6800 6600>,
			<6400 6200 6000 5800 5600 5400>,
			<5200 5000 4800 4600 4400 4200>,
			<4000 3800 3600 3400 3200 3000>,
			<2800 2600 2400 2200 2000 1800>,
			<1600 1400 1200 1000 900 800>,
			<700 600 500 400 300 200>,
			<100 0>;
		qcom,lut-data = <9798 15371 14929 17674 19751 19323>,
			<11404 14412 15643 17862 19097 19271>,
			<12729 14105 16354 17977 18456 19120>,
			<13736 14316 16970 18030 17854 18889>,
			<14386 14913 17400 18029 17314 18600>,
			<14640 15770 17552 17983 16860 18273>,
			<14327 18138 17388 17764 16484 17817>,
			<13821 20867 17162 17486 16154 17314>,
			<13706 20124 17950 17360 15790 16955>,
			<13687 14814 21322 17089 15293 16673>,
			<14042 11777 23066 16757 15081 16416>,
			<17812 13989 18671 15884 15697 16075>,
			<22598 17473 13109 14941 16464 15799>,
			<22030 19190 13717 14818 16350 15864>,
			<16700 20110 18307 14850 15606 16190>,
			<13758 20323 20757 14848 15109 16329>,
			<14413 18728 20977 14496 14905 15753>,
			<15279 16965 21141 14102 14791 15062>,
			<15344 17483 21614 14871 14791 14932>,
			<15075 18778 22458 17741 14830 14885>,
			<14677 19337 22974 20111 14994 14973>,
			<13719 18436 23171 21803 17064 17191>,
			<12762 16856 23348 22917 19493 19514>,
			<12646 15151 23762 23036 20434 19557>,
			<12645 13072 24449 22938 21082 19142>,
			<12655 12235 24318 22859 21187 18582>,
			<12822 12338 18167 22756 20150 17530>,
			<13067 12519 12192 22608 18793 16605>,
			<13219 12663 12289 22417 17733 16325>,
			<13341 12870 13401 22189 16766 16162>,
			<13438 13041 14103 22106 16641 16087>,
			<13565 13226 14893 22159 17966 16040>,
			<13673 13401 15504 22214 19272 16019>,
			<13707 13571 15293 22249 19660 16964>,
			<13722 13879 14623 22328 19977 19078>,
			<13690 14119 14327 22314 20293 20053>,
			<13602 14273 14231 22005 20784 20440>,
			<13507 14410 14183 21533 21089 20641>,
			<13411 14641 14229 20705 20886 20781>,
			<13247 15028 14331 19335 20419 20990>,
			<13106 15186 14353 18156 20012 21074>,
			<13021 14896 14299 17037 19637 21178>,
			<13084 14574 14237 16327 18552 20708>,
			<13335 14269 14134 15885 16348 18999>,
			<13764 13800 14050 15213 16024 17594>,
			<14553 13739 14046 15656 17142 17524>,
			<15013 13960 13882 15805 16982 16243>,
			<15426 14031 14220 16254 16334 15898>,
			<15949 14329 14253 16214 16383 15244>,
			<16161 15061 14972 16583 16261 15101>,
			<15619 15038 14660 17387 17728 16440>,
			<15428 14861 14196 18747 19201 16483>,
			<15188 15683 14379 18758 19800 17517>,
			<13141 17069 15162 19485 23597 24965>,
			<13141 17069 15162 19485 23597 24965>,
			<13141 17069 15162 19485 23597 24965>;
	};

	qcom,pc-temp-y6-lut {
		qcom,lut-col-legend = <(-10) 0 10 25 40 50>;
		qcom,lut-row-legend = <10000 9800 9600 9400 9200 9000>,
			<8800 8600 8400 8200 8000 7800>,
			<7600 7400 7200 7000 6800 6600>,
			<6400 6200 6000 5800 5600 5400>,
			<5200 5000 4800 4600 4400 4200>,
			<4000 3800 3600 3400 3200 3000>,
			<2800 2600 2400 2200 2000 1800>,
			<1600 1400 1200 1000 900 800>,
			<700 600 500 400 300 200>,
			<100 0>;
		qcom,lut-data = <6492 5916 5430 5120 5047 5032>,
			<6448 5910 5442 5120 5046 5031>,
			<6406 5902 5449 5120 5046 5031>,
			<6365 5894 5453 5120 5046 5030>,
			<6326 5887 5454 5120 5046 5030>,
			<6289 5883 5454 5120 5046 5031>,
			<6246 5882 5449 5120 5046 5031>,
			<6211 5881 5442 5120 5047 5032>,
			<6207 5874 5441 5121 5048 5033>,
			<6219 5848 5443 5123 5049 5034>,
			<6226 5834 5446 5125 5050 5035>,
			<6232 5872 5452 5126 5052 5036>,
			<6237 5923 5459 5128 5055 5037>,
			<6203 5905 5461 5131 5058 5039>,
			<6075 5798 5457 5139 5061 5042>,
			<6005 5729 5451 5144 5064 5045>,
			<6004 5714 5429 5146 5068 5047>,
			<6004 5705 5403 5149 5073 5050>,
			<6001 5699 5393 5154 5078 5056>,
			<5991 5690 5388 5163 5085 5064>,
			<5987 5680 5380 5167 5087 5066>,
			<5987 5664 5361 5145 5074 5056>,
			<5987 5649 5341 5119 5057 5043>,
			<5990 5648 5332 5109 5049 5035>,
			<6001 5650 5326 5103 5043 5028>,
			<6014 5654 5321 5101 5041 5026>,
			<6027 5666 5315 5101 5042 5026>,
			<6041 5686 5311 5102 5042 5027>,
			<6058 5705 5315 5103 5043 5028>,
			<6079 5726 5327 5105 5046 5031>,
			<6101 5751 5339 5106 5049 5035>,
			<6126 5779 5353 5107 5054 5039>,
			<6153 5812 5370 5108 5057 5042>,
			<6180 5847 5392 5110 5057 5043>,
			<6209 5886 5419 5114 5056 5044>,
			<6240 5924 5449 5117 5054 5044>,
			<6272 5963 5483 5119 5050 5036>,
			<6304 6001 5520 5123 5047 5030>,
			<6338 6038 5559 5127 5047 5031>,
			<6373 6073 5601 5131 5049 5034>,
			<6410 6102 5643 5137 5051 5037>,
			<6452 6122 5684 5148 5055 5042>,
			<6498 6145 5726 5158 5055 5041>,
			<6552 6175 5770 5169 5049 5030>,
			<6606 6219 5816 5181 5051 5031>,
			<6578 6222 5829 5178 5059 5042>,
			<6632 6263 5869 5192 5068 5054>,
			<6686 6308 5917 5206 5080 5065>,
			<6741 6351 5961 5221 5091 5075>,
			<6798 6389 6005 5234 5094 5077>,
			<6860 6419 6022 5222 5070 5047>,
			<6968 6479 6090 5238 5069 5047>,
			<7315 6575 6215 5263 5079 5053>,
			<8852 6831 6364 5304 5103 5075>,
			<8852 6831 6364 5304 5103 5075>,
			<8852 6831 6364 5304 5103 5075>;
	};

};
